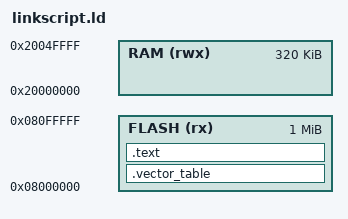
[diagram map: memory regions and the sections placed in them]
MEMORY
{
  FLASH (rx) : ORIGIN = 0x08000000, LENGTH = 1024K
  RAM (rwx)  : ORIGIN = 0x20000000, LENGTH = 320K
}

SECTIONS
{
  .vector_table :
  {
    . = ALIGN(4);
    KEEP(*(.vector_table))
    . = ALIGN(4);
  } > FLASH

  .text :
  {
    . = ALIGN(4);
    *(.text)
    *(.text*)
    . = ALIGN(4);
  } > FLASH

  /* 기타 필요한 섹션들 */
}
